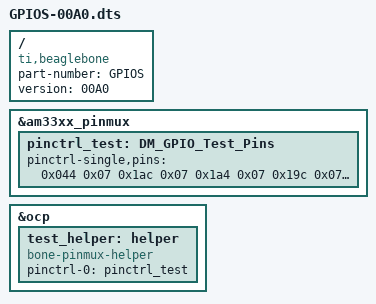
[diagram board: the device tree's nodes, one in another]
/* Copile with: dtc -O dtb -o GPIOS-00A0.dtbo -b 0 -@ GPIOS-00A0.dts */

/dts-v1/;
/plugin/;

/{
    compatible = "ti,beaglebone", "ti,beaglebone-black";
    part-number = "GPIOS";
    version = "00A0";
    fragment@0 {
        target = <&am33xx_pinmux>;
        __overlay__ {
            pinctrl_test: DM_GPIO_Test_Pins {
                pinctrl-single,pins = <
                    /* 0x044 0x07 */  /* P9_23 49  OUTPUT MODE7 - MUXA */
                    /* 0x040 0x07 */  /* P9_15 48  OUTPUT MODE7 - MUXB */
                    /* 0x1ac 0x07 */  /* P9_25 117 OUTPUT MODE7 - MUXT conflict mcasp0! */
                    /* 0x0a4 0x07 */  /* P8_46 71  OUTPUT MODE7 - RTS conflict hdmi_bonelt! */

                    /* Refence: https://github.com/jadonk/bonescript/blob/64732854d4c296de8792d5d4c49639ae5f5ecede/src/bone.js */

                    /* P9 */
                    0x044 0x07  /* P9_23 49  OUTPUT MODE7 - CS1 */
                    0x1ac 0x07  /* P9_25 117 OUTPUT MODE7 - CS2 */
                    0x1a4 0x07  /* P9_27 115 OUTPUT MODE7 - SHDN2 */
                    0x19c 0x07  /* P9_28 113 OUTPUT MODE7 - LDAC2 */
                    0x194 0x07  /* P9_29 111 OUTPUT MODE7 - LDAC1 */
                    0x198 0x07  /* P9_30 112 OUTPUT MODE7 - SHDN1 */

                    /* OUTPUT  GPIO(mode7) 0x07 pulldown, 0x17 pullup, 0x?f no pullup/down */
                    /* INPUT   GPIO(mode7) 0x27 pulldown, 0x37 pullup, 0x?f no pullup/down */
                >;
            };
        };
    };

    fragment@1 {
        target = <&ocp>;
        __overlay__ {
            test_helper: helper {
                compatible = "bone-pinmux-helper";
                pinctrl-names = "default";
                pinctrl-0 = <&pinctrl_test>;
                status = "okay";
            };
        };
    };
};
